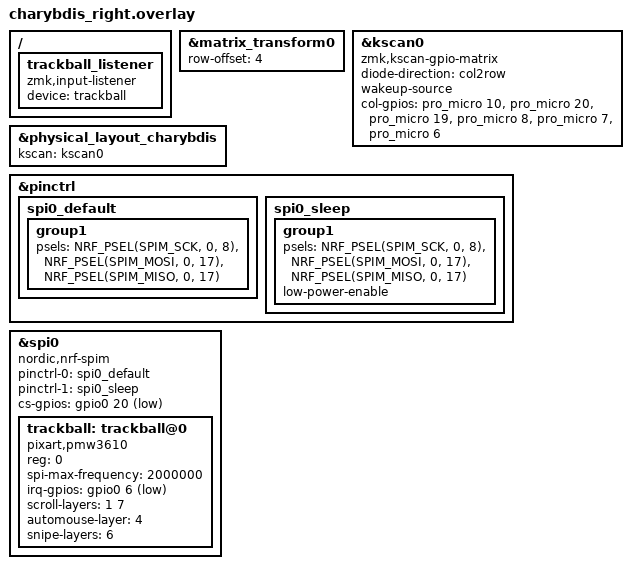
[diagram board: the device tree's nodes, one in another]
/*
 * Copyright (c) 2020 ZMK Contributors
 *
 * SPDX-License-Identifier: MIT
 */
 
#include "charybdis.dtsi"

&matrix_transform0 {
    row-offset = <4>;
};

&kscan0 {
    compatible = "zmk,kscan-gpio-matrix";
            diode-direction = "col2row";
            wakeup-source;
    col-gpios
            = <&pro_micro 10 GPIO_ACTIVE_HIGH>
            , <&pro_micro 20 GPIO_ACTIVE_HIGH>
            , <&pro_micro 19 GPIO_ACTIVE_HIGH>
            , <&pro_micro 8 GPIO_ACTIVE_HIGH>
            , <&pro_micro 7 GPIO_ACTIVE_HIGH>
            , <&pro_micro 6 GPIO_ACTIVE_HIGH>
    ;
};

&physical_layout_charybdis {
    kscan = <&kscan0>;
};


&pinctrl {
    spi0_default: spi0_default {
        group1 {
            psels = <NRF_PSEL(SPIM_SCK, 0, 8)>,
                <NRF_PSEL(SPIM_MOSI, 0, 17)>,
                <NRF_PSEL(SPIM_MISO, 0, 17)>;
        };
    };

    spi0_sleep: spi0_sleep {
        group1 {
            psels = <NRF_PSEL(SPIM_SCK, 0, 8)>, // pro micro D0
                <NRF_PSEL(SPIM_MOSI, 0, 17)>, // pro micro D2
                <NRF_PSEL(SPIM_MISO, 0, 17)>; // pro micro D2
            low-power-enable;
        };
    };
};

&spi0 {
    status = "okay";
    compatible = "nordic,nrf-spim";
    pinctrl-0 = <&spi0_default>;
    pinctrl-1 = <&spi0_sleep>;
    pinctrl-names = "default", "sleep";
    cs-gpios = <&gpio0 20 GPIO_ACTIVE_LOW>; // pro micro D3

    trackball: trackball@0 {
        status = "okay";
        compatible = "pixart,pmw3610";
        reg = <0>;
        spi-max-frequency = <2000000>;
        irq-gpios = <&gpio0 6 (GPIO_ACTIVE_LOW | GPIO_PULL_UP)>; // pro micro D1
         /*   optional features   */
        scroll-layers = <1 7>;
        automouse-layer = <4>;
        snipe-layers = <6>;
    };
};

/ {
  trackball_listener {
    compatible = "zmk,input-listener";
    device = <&trackball>;
  };
};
